# A31R71x register map
Vendor: VENDOR ABOV Semiconductor Co., Ltd.; Series: A31R71x; File version: 1.0
CPU: CM0+ r0p1, little endian, no MPU, no FPU, VTOR, 2 interrupt priority bits
Registers are 32-bit, read-write, reset 0x0 unless marked. A register's access mark holds for its fields unless they carry their own. Offsets are from the block's base; [hi:lo] are bit positions.

## FMC — Flash Memory Controller
Base 0x40001B00
0x00 ADR reset 0x5FFFFF80 — Flash Memory Address Register
  [31:0] ADDR — Flash Memory Address Pointer
0x04 IDR1 — Flash Memory Identification Register 1
  [31:0] ID1 — Flash Memory Identification 1
0x08 IDR2 — Flash Memory Identification Register 2
  [31:0] ID2 — Flash Memory Identification 2
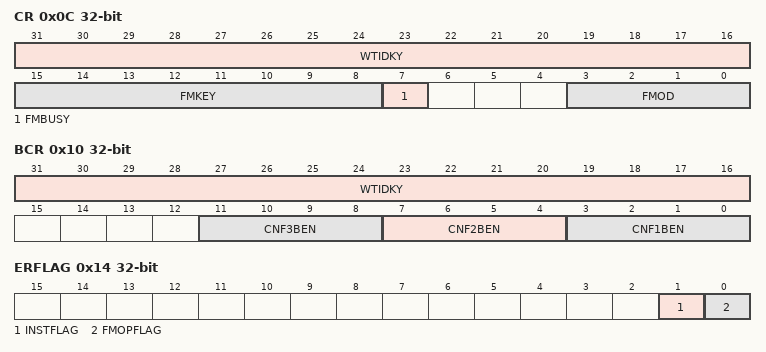
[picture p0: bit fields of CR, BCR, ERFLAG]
0x0C CR — Flash Memory Control Register
  [31:16] WTIDKY wo — Write Identification Key (0x6c93)
    0x6C93=Value (Key Value (0x6c93))
  [15:8] FMKEY — Flash Memory Operation Area Selection
  [7] FMBUSY ro — Flash Memory Operation Mode Busy
  [3:0] FMOD — Flash Memory Operation Mode Selection
0x10 BCR — Flash Memory Configure Area Bulk Erase Control Register
  [31:16] WTIDKY wo — Write Identification Key (0xc1be)
    0xC1BE=Value (Key Value (0xc1be))
  [11:8] CNF3BEN — Configure Option Page 3 Bulk Erase Enable
  [7:4] CNF2BEN — Configure Option Page 2 Bulk Erase Enable
  [3:0] CNF1BEN — Configure Option Page 1 Bulk Erase Enable
0x14 ERFLAG — Flash Memory Error Flag
  [1] INSTFLAG — Don't care
  [0] FMOPFLAG — Error bit of Flash Memory Operation Procedure
0x100 PAGEBUF wo — Flash Memory Page Buffer Area (128bytes/Accessed by 32bit Word Only)

## WDT — Watch-Dog Timer
Base 0x40001A00
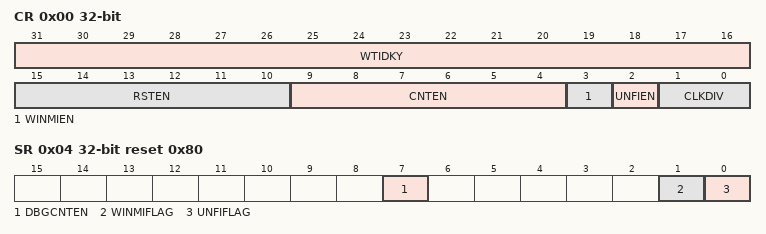
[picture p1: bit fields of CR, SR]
0x00 CR — Watch-Dog Timer Control Register
  [31:16] WTIDKY wo — Write Identification Key (0x5a69)
    0x5A69=Value (Key Value (0x5a69))
  [15:10] RSTEN — Watch-Dog Timer Reset Enable
    37=Disable Watch-Dog Timer reset. (0x25); 0=Enable Watch-Dog Timer reset
  [9:4] CNTEN — Watch-Dog Timer Counter Enable
    26=Disable Watch-Dog Timer counter. (0x1a); 0=Enable Watch-Dog Timer counter
  [3] WINMIEN — Watch-Dog Timer Window Match Interrupt Enable
    0=Disable window data match interrupt; 1=Enable window data match interrupt
  [2] UNFIEN — Watch-Dog Timer Underflow Interrupt Enable
    0=Disable Watch-Dog Timer underflow interrupt; 1=Enable Watch-Dog Timer underflow interrupt
  [1:0] CLKDIV — Watch-Dog Timer Clock Divider
    0=fWDT4; 1=fWDT16; 2=fWDT64; 3=fWDT256
0x04 SR reset 0x80 — Watch-Dog Timer Status Register
  [7] DBGCNTEN — Watch-Dog Timer Counter Enable when the core is halted in debug mode
    0=Run (The Watch-Dog Timer counter continues even if the core is halted); 1=Stop (The Watch-Dog Timer counter is stopped when the core is halted)
  [1] WINMIFLAG — Watch-Dog Timer Window Match Interrupt Flag
    0=No request occurred; 1=Request occurred
  [0] UNFIFLAG — Watch-Dog Timer Underflow Interrupt Flag
    0=No request occurred; 1=Request occurred
0x08 DR reset 0xFFF — Watch-Dog Timer Data Register
  [23:0] DATA — Watch-Dog Timer Data
0x0C CNT ro reset 0xFFF — Watch-Dog Timer Counter Register
  [23:0] CNT — Watch-Dog Timer Counter
0x10 WINDR reset 0x1FFF — Watch-Dog Timer Window Data Register
  [23:0] WDATA — Watch-Dog Timer Window Data
0x14 CNTR wo — Watch-Dog Timer Counter Reload Register
  [7:0] CNTR — Watch-Dog Timer Counter Reload
    106=Reload the WDTDR value to Watch-Dog Timer counter and re-start. (0x6a) (Automatically cleared to '0x00' after operation.); 0=NoEffect

## WT — Watch Timer
Base 0x40002000
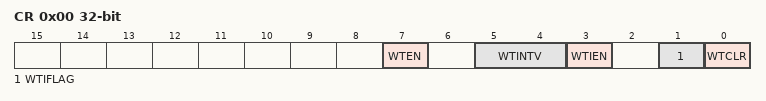
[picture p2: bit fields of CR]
0x00 CR — Watch Timer Control Register
  [7] WTEN — Watch Timer Operation Enable
    0=Disable watch timer operation; 1=Enable watch timer operation
  [5:4] WTINTV — Watch Timer Interval Selection
    0=fWT2Pow7 (fWT/2^7); 1=fWT2Pow13 (fWT/2^13); 2=fWT2Pow14 (fWT/2^14); 3=fWT2Pow14DR (fWT/(2^14x(WTDR value + 1)))
  [3] WTIEN — Watch Timer Interrupt Enable
    0=Disable watch timer interrupt; 1=Enable watch timer interrupt
  [1] WTIFLAG — Watch Timer Interrupt Flag
    0=No request occurred; 1=Request occurred
  [0] WTCLR — Watch Timer Counter and Divider Clear
    0=NoEffect; 1=Clear the counter and divider. (Automatically cleared to '0b' after operation)
0x04 DR reset 0xFFF — Watch Timer Data Register
  [11:0] WTDATA — Watch Timer Data
0x08 CNT ro — Watch Timer Counter Register
  [11:0] CNT — Watch Timer Counter
